# Timer0_D3_1 register map
Vendor: Texas Instruments
Peripheral module from a debugger description file (folder msp430).
Registers are 16-bit, read-write, reset 0x0 unless marked. A register's access mark holds for its fields unless they carry their own. Offsets are as the file gives them; lines under a group give offsets from that group; [hi:lo] are bit positions; {n}, {i} and the like mark numbered series; 'fields as' and 'values as' point back to an identical list; <NAME> marks a mode.

## Timer0_D3
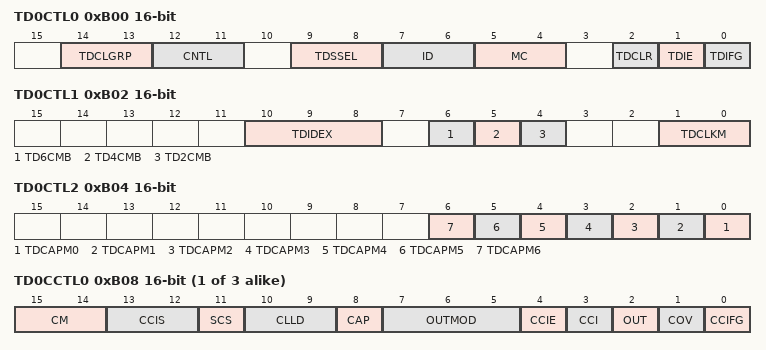
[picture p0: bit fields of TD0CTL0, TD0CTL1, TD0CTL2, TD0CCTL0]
0xB00 TD0CTL0 — Timer0_D3 Control 0
  [14:13] TDCLGRP — Timer0_D3 Compare latch load group 1
    0=Timer0_D3 Group: 0 - individually; 1=Timer0_D3 Group: 1 - 3 groups (1-2; 2=Timer0_D3 Group: 2 - 2 groups (1-3; 3=Timer0_D3 Group: 3 - 1 group (all)
  [12:11] CNTL — Counter lenght 1
    0=Counter lenght: 16 bit; 1=Counter lenght: 12 bit; 2=Counter lenght: 10 bit; 3=Counter lenght: 8 bit
  [9:8] TDSSEL — Clock source 1
    0=Clock Source: TDCLK; 1=Clock Source: ACLK; 2=Clock Source: SMCLK; 3=Clock Source: INCLK
  [7:6] ID — Timer0_D3 clock input divider 1
    0=Timer A input divider: 0 - /1; 1=Timer A input divider: 1 - /2; 2=Timer A input divider: 2 - /4; 3=Timer A input divider: 3 - /8
  [5:4] MC — Timer0_D3 mode control 1
    0=Timer A mode control: 0 - Stop; 1=Timer A mode control: 1 - Up to CCR0; 2=Timer A mode control: 2 - Continuous up; 3=Timer A mode control: 3 - Up/Down
  [2] TDCLR — Timer0_D3 counter clear
  [1] TDIE — Timer0_D3 interrupt enable
  [0] TDIFG — Timer0_D3 interrupt flag
0xB02 TD0CTL1 — Timer0_D3 Control 1
  [10:8] TDIDEX — Timer0_D3 Input divider expansion Bit: 0
    {v}=Timer0_D3 Input divider expansion : /{v+1} (v=0..7)
  [6] TD6CMB — Timer0_D3 TD0CCR Combination in TD6
  [5] TD4CMB — Timer0_D3 TD0CCR Combination in TD4
  [4] TD2CMB — Timer0_D3 TD0CCR Combination in TD2
  [1:0] TDCLKM — Timer0_D3 Clocking Mode Bit: 0
    0=Timer0_D3 Clocking Mode: External; 1=Timer0_D3 Clocking Mode: High-Res. local clock; 2=Timer0_D3 Clocking Mode: Aux Clock
0xB04 TD0CTL2 — Timer0_D3 Control 2
  [n] TDCAPM{n} (n=0..6) — Timer0_D3 Capture Mode of Channel {n}
0xB06 TD0R access not given reset not defined — Timer0_D3 Counter
{0xB08+6i} TD0CCTL{i} (i=0..2) — Timer0_D3 Capture/Compare Control {i}
  [15:14] CM — Capture mode 1
    0=Capture mode: 0 - disabled; 1=Capture mode: 1 - pos. edge; 2=Capture mode: 1 - neg. edge; 3=Capture mode: 1 - both edges
  [13:12] CCIS — Capture input select 1
    0=Capture input select: 0 - CCIxA; 1=Capture input select: 1 - CCIxB; 2=Capture input select: 2 - GND; 3=Capture input select: 3 - Vcc
  [11] SCS — Capture sychronize
  [10:9] CLLD — Compare latch load source 1
    0=Compare latch load sourec : 0 - immediate; 1=Compare latch load sourec : 1 - TDR counts to 0; 2=Compare latch load sourec : 2 - up/down; 3=Compare latch load sourec : 3 - TDR counts to TDCTL0
  [8] CAP — Capture mode: 1 /Compare mode : 0
  [7:5] OUTMOD — Output mode 2
    0=PWM output mode: 0 - output only; 1=PWM output mode: 1 - set; 2=PWM output mode: 2 - PWM toggle/reset; 3=PWM output mode: 3 - PWM set/reset; 4=PWM output mode: 4 - toggle; 5=PWM output mode: 5 - Reset; 6=PWM output mode: 6 - PWM toggle/set; 7=PWM output mode: 7 - PWM reset/set
  [4] CCIE — Capture/compare interrupt enable
  [3] CCI — Capture input signal (read)
  [2] OUT — PWM Output signal if output mode 0
  [1] COV — Capture/compare overflow flag
  [0] CCIFG — Capture/compare interrupt flag
{0xB0A+6i} TD0CCR{i} access not given reset not defined (i=0..2) — Timer0_D3 Capture/Compare {i}
{0xB0C+6i} TD0CL{i} access not given reset not defined (i=0..2) — Timer0_D3 Capture/Compare Latch {i}
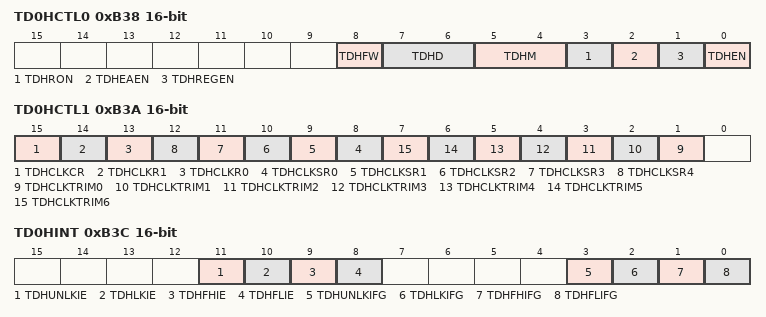
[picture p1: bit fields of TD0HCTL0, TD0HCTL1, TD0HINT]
0xB38 TD0HCTL0 — Timer0_D3 High-resolution Control Register 0
  [8] TDHFW — Timer0_D7 High-resolution generator fast wakeup enable
  [7:6] TDHD — Timer0_D3 High-Resolution clock divider Bit: 0
    0=Timer0_D3 High-Resolution clock divider: /1; 1=Timer0_D3 High-Resolution clock divider: /2; 2=Timer0_D3 High-Resolution clock divider: /4; 3=Timer0_D3 High-Resolution clock divider: /8
  [5:4] TDHM — Timer0_D3 High-Resoltuion Clock Mult. Bit: 0
    0=Timer0_D3 High-Resoltuion Clock Mult.: 8x TimerD clock; 1=Timer0_D3 High-Resoltuion Clock Mult.: 16x TimerD clock
  [3] TDHRON — Timer0_D3 High-Resolution Generator forced on
  [2] TDHEAEN — Timer0_D3 High-Resolution clock error accum. enable
  [1] TDHREGEN — Timer0_D3 High-Resolution Regulated Mode
  [0] TDHEN — Timer0_D3 High-Resolution Enable
0xB3A TD0HCTL1 — Timer0_D3 High-resolution Control Register 1
  [15] TDHCLKCR — Timer0_D3 High-Resolution Coarse Clock Range
  [14] TDHCLKR1 — Timer0_D3 High-Resolution Clock Range Bit: 1
  [13] TDHCLKR0 — Timer0_D3 High-Resolution Clock Range Bit: 0
  [n+8] TDHCLKSR{n} (n=0..4) — Timer0_D3 High-Resolution Clock Sub-Range Bit: {n}
  [n+1] TDHCLKTRIM{n} (n=0..6) — Timer0_D3 High-Resolution Clock Trim Bit: {n}
0xB3C TD0HINT — Timer0_D3 High-resolution Interrupt Register
  [11] TDHUNLKIE — Timer0_D3 High-Res. frequency unlock Interrupt Enable
  [10] TDHLKIE — Timer0_D3 High-Res. frequency lock Interrupt Enable
  [9] TDHFHIE — Timer0_D3 High-Res. fail high Interrupt Enable
  [8] TDHFLIE — Timer0_D3 High-Res. fail low Interrupt Enable
  [3] TDHUNLKIFG — Timer0_D3 High-Res. frequency unlock Interrupt Flag
  [2] TDHLKIFG — Timer0_D3 High-Res. frequency lock Interrupt Flag
  [1] TDHFHIFG — Timer0_D3 High-Res. fail high Interrupt Flag
  [0] TDHFLIFG — Timer0_D3 High-Res. fail low Interrupt Flag
0xB3E TD0IV access not given reset not defined — Timer0_D3 Interrupt Vector Word
